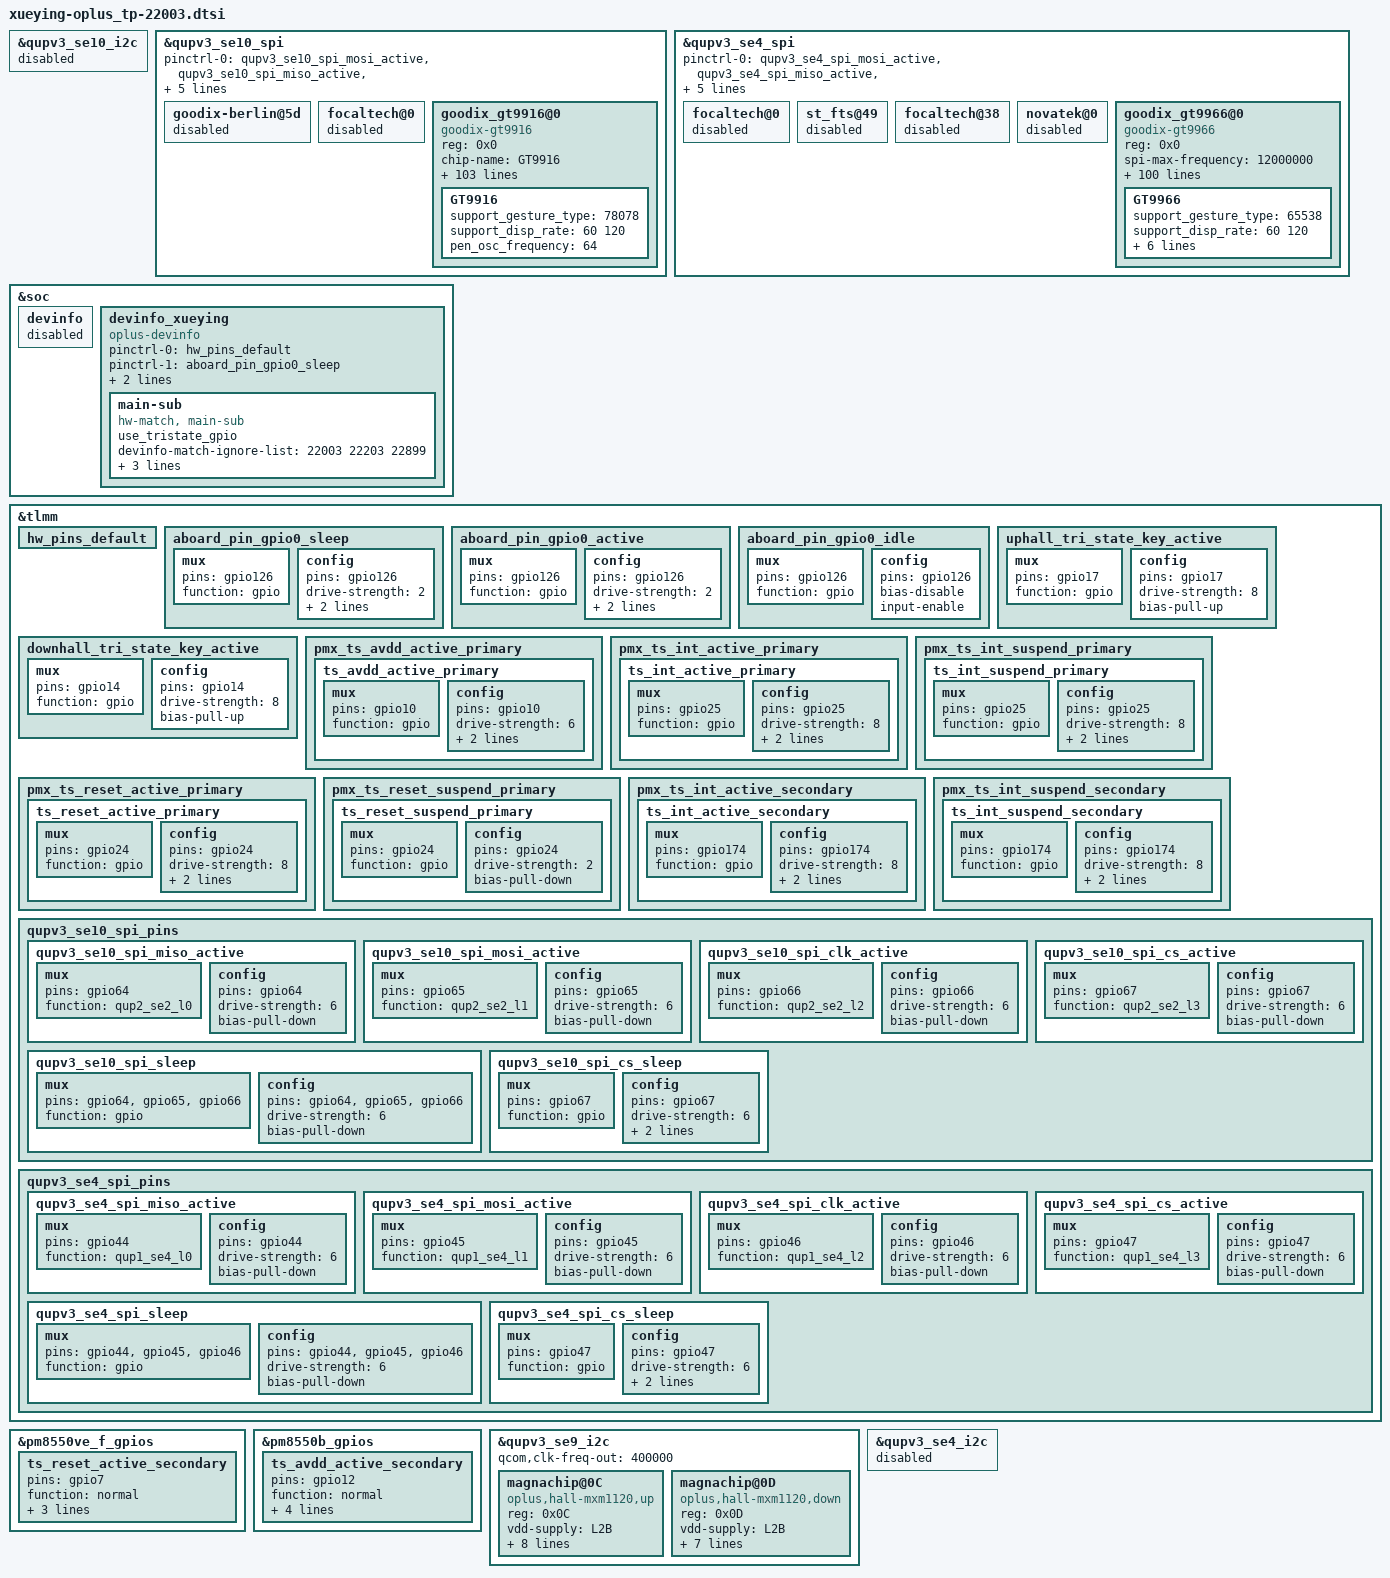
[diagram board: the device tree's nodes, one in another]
&qupv3_se10_i2c {
	status = "disabled";
};

&qupv3_se10_spi{
	/delete-property/ pinctrl-0;
	/delete-property/ pinctrl-1;
	pinctrl-0 = <&qupv3_se10_spi_mosi_active>, <&qupv3_se10_spi_miso_active>,
				<&qupv3_se10_spi_clk_active>, <&qupv3_se10_spi_cs_active>;
	pinctrl-1 = <&qupv3_se10_spi_sleep>, <&qupv3_se10_spi_cs_sleep>;
};

&qupv3_se4_spi{
	/delete-property/ pinctrl-0;
	/delete-property/ pinctrl-1;
	pinctrl-0 = <&qupv3_se4_spi_mosi_active>, <&qupv3_se4_spi_miso_active>,
				<&qupv3_se4_spi_clk_active>, <&qupv3_se4_spi_cs_active>;
	pinctrl-1 = <&qupv3_se4_spi_sleep>, <&qupv3_se4_spi_cs_sleep>;
};

&soc {
    devinfo {
        status = "disabled";
    };

	devinfo_xueying {
		compatible = "oplus-devinfo";

		pinctrl-names = "default", "sleep", "active", "idle";
		pinctrl-0 = <&hw_pins_default>;
		pinctrl-1 = <&aboard_pin_gpio0_sleep>;
		pinctrl-2 = <&aboard_pin_gpio0_active>;
		pinctrl-3 = <&aboard_pin_gpio0_idle>;

		main-sub {
			use_tristate_gpio;
			devinfo-match-ignore-list = <22003 22203 22899>;
			compatible = "hw-match, main-sub";
			aboard-gpio0 = <&tlmm 126 0>;
			aboard-patterns = <0 0 0>;	/*0[high-resistance] 1[pull-down] 2[pull-up]*/
			/*main board*/
			match-projects = <22003 22203 22899>;
		};
	};
};

&tlmm {
//#ifdef OPLUS_FEATURE_TP_BASIC
//#ifdef OPLUS_FEATURE_ABOARD
	hw_pins_default:hw_pins_default {
	};
	aboard_pin_gpio0_sleep:aboard_pin_gpio0_sleep {
		mux {
			pins = "gpio126";
			function = "gpio";
		};
		config {
			pins = "gpio126";
			drive-strength = <2>;
			bias-pull-down;
			input-enable;
		};
	};

	aboard_pin_gpio0_active:aboard_pin_gpio0_active {
		mux {
			pins = "gpio126";
			function = "gpio";
		};
		config {
			pins = "gpio126";
			drive-strength = <2>;
			bias-pull-up;
			input-enable;
		};
	};

	aboard_pin_gpio0_idle:aboard_pin_gpio0_idle {
		mux {
			pins = "gpio126";
			function = "gpio";
		};
		config {
			pins = "gpio126";
			bias-disable;
			input-enable;
		};
	};

//#ifdef OPLUS_FEATURE_TRI_KEY
	uphall_tri_state_key_active: uphall_tri_state_key_active {
		mux {
			pins = "gpio17";
			function = "gpio";
		};
		config {
			pins = "gpio17";
			drive-strength = <8>;
			bias-pull-up;
		};
	};

	downhall_tri_state_key_active: downhall_tri_state_key_active {
		mux {
			pins = "gpio14";
			function = "gpio";
		};
		config {
			pins = "gpio14";
			drive-strength = <8>;
			bias-pull-up;
		};
	};
/*
	gpio_wakeup: gpio_wakeup {
		compatible = "gpio_wakeup";
		gpio_table = <207>;
	};
*/
	/* add primary for touchscreen */
	pmx_ts_avdd_active_primary {
		ts_avdd_active_primary: ts_avdd_active_primary {
			mux {
				pins = "gpio10";
				function = "gpio";
			};

			config {
				pins = "gpio10";
				drive-strength = <6>;
				bias-pull-down;
				input-enable;
			};
		};
	};

	pmx_ts_int_active_primary {
		ts_int_active_primary: ts_int_active_primary {
			mux {
				pins = "gpio25";
				function = "gpio";
			};

			config {
				pins = "gpio25";
				drive-strength = <8>;
				bias-disable;
				input-enable;
			};
		};
	};

	pmx_ts_int_suspend_primary {
		ts_int_suspend_primary: ts_int_suspend_primary {
			mux {
				pins = "gpio25";
				function = "gpio";
			};

			config {
				pins = "gpio25";
				drive-strength = <8>;
				//bias-pull-down;
				bias-pull-up;
				input-enable;
			};
		};
	};

	pmx_ts_reset_active_primary {
		ts_reset_active_primary: ts_reset_active_primary {
			mux {
				pins = "gpio24";
				function = "gpio";
			};

			config {
				pins = "gpio24";
				drive-strength = <8>;
				output-low;
				bias-disable;
			};
		};
	};

	pmx_ts_reset_suspend_primary {
		ts_reset_suspend_primary: ts_reset_suspend_primary {
			mux {
				pins = "gpio24";
				function = "gpio";
			};

			config {
				pins = "gpio24";
				drive-strength = <2>;
				bias-pull-down;
			};
		};
	};
	//#endif

	pmx_ts_int_active_secondary {
		ts_int_active_secondary: ts_int_active_secondary {
			mux {
				pins = "gpio174";
				function = "gpio";
			};

			config {
				pins = "gpio174";
				drive-strength = <8>;
				bias-disable;
				input-enable;
			};
		};
	};

	pmx_ts_int_suspend_secondary {
		ts_int_suspend_secondary: ts_int_suspend_secondary {
			mux {
				pins = "gpio174";
				function = "gpio";
			};

			config {
				pins = "gpio174";
				drive-strength = <8>;
				//bias-pull-down;
				bias-pull-up;
				input-enable;
			};
		};
	};

	qupv3_se10_spi_pins: qupv3_se10_spi_pins {
		qupv3_se10_spi_miso_active: qupv3_se10_spi_miso_active {
			mux {
				pins = "gpio64";
				function = "qup2_se2_l0";
			};

			config {
				pins = "gpio64";
				drive-strength = <6>;
				bias-pull-down;
			};
		};

		qupv3_se10_spi_mosi_active: qupv3_se10_spi_mosi_active {
			mux {
				pins = "gpio65";
				function = "qup2_se2_l1";
			};

			config {
				pins = "gpio65";
				drive-strength = <6>;
				bias-pull-down;
			};
		};

		qupv3_se10_spi_clk_active: qupv3_se10_spi_clk_active {
			mux {
				pins = "gpio66";
				function = "qup2_se2_l2";
			};

			config {
				pins = "gpio66";
				drive-strength = <6>;
				bias-pull-down;
			};
		};

		qupv3_se10_spi_cs_active: qupv3_se10_spi_cs_active {
			mux {
				pins = "gpio67";
				function = "qup2_se2_l3";
			};

			config {
				pins = "gpio67";
				drive-strength = <6>;
				bias-pull-down;
			};
		};

		qupv3_se10_spi_sleep: qupv3_se10_spi_sleep {
			mux {
				pins = "gpio64", "gpio65",
					"gpio66";
				function = "gpio";
			};

			config {
				pins = "gpio64", "gpio65",
					"gpio66";
				drive-strength = <6>;
				bias-pull-down;
			};
		};

		qupv3_se10_spi_cs_sleep: qupv3_se10_spi_cs_sleep {
			mux {
				pins = "gpio67";
				function = "gpio";
			};

			config {
				pins = "gpio67";
				drive-strength = <6>;
				bias-disable;
				output-high;
			};
		};
	};

	qupv3_se4_spi_pins: qupv3_se4_spi_pins {
			qupv3_se4_spi_miso_active: qupv3_se4_spi_miso_active {
					mux {
							pins = "gpio44";
							function = "qup1_se4_l0";
					};

					config {
							pins = "gpio44";
							drive-strength = <6>;
							bias-pull-down;
					};
			};

			qupv3_se4_spi_mosi_active: qupv3_se4_spi_mosi_active {
					mux {
							pins = "gpio45";
							function = "qup1_se4_l1";
					};

					config {
							pins = "gpio45";
							drive-strength = <6>;
							bias-pull-down;
					};
			};

			qupv3_se4_spi_clk_active: qupv3_se4_spi_clk_active {
					mux {
							pins = "gpio46";
							function = "qup1_se4_l2";
					};

					config {
							pins = "gpio46";
							drive-strength = <6>;
							bias-pull-down;
					};
			};

			qupv3_se4_spi_cs_active: qupv3_se4_spi_cs_active {
					mux {
							pins = "gpio47";
							function = "qup1_se4_l3";
					};

					config {
							pins = "gpio47";
							drive-strength = <6>;
							bias-pull-down;
					};
			};

			qupv3_se4_spi_sleep: qupv3_se4_spi_sleep {
					mux {
							pins = "gpio44", "gpio45",
									"gpio46";
							function = "gpio";
					};

					config {
							pins = "gpio44", "gpio45",
									"gpio46";
							drive-strength = <6>;
							bias-pull-down;
					};
			};

			qupv3_se4_spi_cs_sleep: qupv3_se4_spi_cs_sleep {
				mux {
					pins = "gpio47";
					function = "gpio";
				};

				config {
					pins = "gpio47";
					drive-strength = <6>;
					bias-disable;
					output-high;
				};
			};
	};
};

&pm8550ve_f_gpios {
	ts_reset_active_secondary: ts_reset_active_secondary {
		pins = "gpio7";
		function = "normal";
		bias-disable;
		output-low;
		power-source = <1>;
	};
};

&pm8550b_gpios {
	ts_avdd_active_secondary: ts_avdd_active_secondary {
		pins = "gpio12";
		function = "normal";
		input-disable;
		output-enable;
		output-low;
		power-source = <0>;
	};
};

&qupv3_se9_i2c {
	status = "ok";
	qcom,clk-freq-out = <400000>;
	magnachip@0C {
		compatible = "oplus,hall-mxm1120,up";
		reg = <0x0C>;
		vdd-supply = <&L2B>;
		vio-supply = <&L1B>;
		magnachip,init-interval = <200>;
		interrupt-parent = <&tlmm>;
		interrups = <17 0x02>;
		dhall,irq-gpio = <&tlmm 17 0x2008>;
		pinctrl-names = "uphall_tri_state_key_active";
		pinctrl-0 = <&uphall_tri_state_key_active>;
		data_offect = <40>;
		esd-check-support;
	};

	magnachip@0D {
		compatible = "oplus,hall-mxm1120,down";
		reg = <0x0D>;
		vdd-supply = <&L2B>;
		vio-supply = <&L1B>;
		magnachip,init-interval = <200>;
		interrupt-parent = <&tlmm>;
		interrups = <14 0x02>;
		dhall,irq-gpio = <&tlmm 14 0x2008>;
		pinctrl-names = "downhall_tri_state_key_active";
		pinctrl-0 = <&downhall_tri_state_key_active>;
		esd-check-support;
	};
};

//#ifdef /*OPLUS_FEATURE_TP_BASIC*/
&qupv3_se4_i2c {
	status = "disabled";
};
&qupv3_se4_spi {
	status = "ok";
	#address-cells = <1>;
	#size-cells = <0>;

	qcom,spi-touch-active = "goodix-gt9966";
	//qcom,la-vm;

	/delete-node/ focaltech@0;
	focaltech@0 {
		status = "disabled";
	};
	st_fts@49 {
		status = "disabled";
	};
	focaltech@38 {
		status = "disabled";
	};
	novatek@0 {
		status = "disabled";
	};

	goodix_gt9966@0 {
		status = "ok";
		compatible = "goodix-gt9966";
		reg = <0x0>;
		spi-max-frequency = <12000000>;
		chip-num = <3>;
		chip-name = "GT9966DVT", "GT9966", "GT9966";
		/* Interrupt && Irq-gpio */
		irq-gpio = <&tlmm 25 0x2002>;
		interrupt-parent = <&tlmm>;
		interrupts = <25 0x2002>;
		reset-gpio = <&tlmm 24 0x1>;

		/* Power Config */
		enable2v8_gpio = <&tlmm 10 0x1>;
		vcc_1v8-supply = <&L4B>;

		/* Other HW Resource */
		pinctrl-names = "default";
		pinctrl-0 = <&ts_avdd_active_primary &ts_int_active_primary &ts_reset_active_primary>;

		touchpanel,max-num-support = <10>;
		touchpanel,tx-rx-num = <36 38>;
		earsense,tx-rx-num = <36 38>;
		touchpanel,panel-coords = <22680 24400>;
		touchpanel,display-coords = <2268 2440>;
		touchpanel,touchmajor-limit = <128 216>;
		touchpanel,single-optimized-time = <8>;
		touchpanel,high-frame-rate-time = <60>;

		touchpanel,pen-tx-rx-num = <36 38>;
		touchpanel,pen-panel-coords = <22680 24400>;
		touchpanel,pen-max-pressure = <4096>;
		touchpanel,pen-max-tilt = <60 60>;
		touchpanel,msecs-to-jiffies-time = <100>;

		touchpanel,smooth-level = <0 47 45 59 57 131>; /* HighByte:previoueFrame; LowByte:currentFrame */
		//touchpanel,smooth-level-charging = <0 47 45 59 57 131>;
		touchpanel,sensitive-level = <0 90 70 60 57 131>;

		project_id = <22003>;
		vid_len = <2>;
		touchpanel,tp-index = <0>;
		panel_type = <3 8 3>; // type of tp_dev ,TP-BOE = 3;
		firmware_name = "AC052", "AC052", "AC052";
		platform_support_project = <22003 22203 22899>;
		platform_support_project_dir = <22003 22003 22003>;
		platform_support_project_commandline = "dsi_panel_AC052_P_3_A0003_dsc_cmd_dvt",
						     "dsi_panel_AC052_P_1_A0002_dsc_cmd",
						     "dsi_panel_AC052_P_3_A0003_dsc_cmd";

		prevention,curved_screen_V2;
		prevention,grip_disable_level = <6>;
		prevention,updelay_time_ms = <30>;
		prevention,makeup_cnt_weight = <5 1 2 2 2>;
		prevention,large_corner_range = <1200 3000>;
		prevention,large_corner_judge_condition = <500 100 1000 7 7>;
		prevention,trx_reject_condition = <9 7 5>;
		prevention,trx_strict_reject_condition = <8 5 5>;
		prevention,large_judge_time_ms = <500 50 100>;
		prevention,large_exit_condition = <8 8 2>;
		prevention,single_channel_width = <320 320>;
		prevention,normal_tap_condition = <10 350>;
		prevention,long_edge_condition = <200 150 40 80>;
		prevention,long_strict_edge_condition = <50 25>;
		prevention,long_fingerhold_condition = <70 6 4 4>;
		prevention,short_edge_condition = <250 90 180 80>;
		prevention,short_strict_edge_condition = <160 60>;
		prevention,large_strict_exit_condition = <4 4>;
		prevention,top_corner_config = <500 1500 300>;
		prevention,edge_swipe_config = <300 1000>;

		prevention,curved_screen_V4;
		prevention,long_eliminate_point_type = <2 22680 8400 300 24400 300 1>;
		prevention,long_fingerhold_condition2 = <650 2000 0 0>;
		prevention,top_corner_config2 = <3 80 600 1500 0>;
		prevention,hor_long_top_corner_config = <350 2270 0 0>;
		prevention,top_middle_config = <22680 1000 1000 0>;
		prevention,corner_eliminate_point_type = <0 1380 2280 1>;
		prevention,finger_hold_differ_size = <1 0 300 300>;
		prevention,finger_hold_max_rx_exit_distance = <5 350 2300>;
		prevention,max_rx_exit_distance = <1 5 150 350 2000>;
		prevention,dynamic_finger_hold_exit_distance = <1 350 2300 450>;

		black_gesture_support;
		pressure_report_support;
		charger_pump_support;
		game_switch_support;
		smart_gesture_support;
		spi_port_support;
		fw_update_app_support;
		//fingerprint_underscreen_support;
		//freq_hop_simulate_support;
		report_flow_unlock_support;
		//screenoff_fingerprint_info_support;
		irq_need_dev_resume_ok;
		//enable_point_auto_change;
		//report_rate_white_list_support;
		kernel_grip_support;
		exception_upload_support;
		//grip_no_driver_support;
		health_monitor_support;
		black_gesture_indep_support;
		//algorithm_support;
		//snr_read_support;
		//touchpanel,get_motor_coord = <0 370 70>;
		sportify_aod_gesture_support;
		temperature_detect_shellback_support;
		pen_support;
		pen_support_opp;
		bus_ready_check_support;
		tp_lcd_suspend_in_lp_support;
		/*
		 *Virtual Key Config:
		 *1:touchpanel,button-type: <virtualkey_type  supportted_button-map>
		 *virtualkey_type:
		 *Type 1: using board_properties
		 *Type 2: using same IC (button zone&& touch zone are seprate)
		 *Type 3: using diffrent IC (button zone&& touch zone are seprate)
		 *Type 4: No need of virtual key process
		 *supportted_button-map:select|menu|home|back
		 *
		 *2:touchpanel,button-map
		 *type (X1,Y1)(X2,Y2)(X3,Y3)(Width_X,Hight_Y)--Only when button-type is 0
		 */
		touchpanel,button-type = <4>;
		touchpanel.button-TRx = <0 0>;

		GT9966 {
			support_gesture_type = <65538>;
			support_disp_rate = <60 120>;
			pen_osc_frequency = <64>; /*16m or 64m osc clk for factory test*/
			need_change_trx_name = "SAMSUNG";
			SAMSUNG = <38 41>;
			need_change_clk_name = "SAMSUNG_CLK";
			SAMSUNG_CLK = <16>;
			hardware_trx_direction = <1>;/* 0:left,right:tx up,down:rx
							1:left,right:rx up,down:tx
							'when usb port faces down' */
		};
	};
//#endif /*OPLUS_FEATURE_TP_BASIC*/
};

&qupv3_se10_spi {
	status = "ok";

	qcom,spi-touch-active = "goodix-gt9916";

	#address-cells = <1>;
	#size-cells = <0>;

	/delete-node/ focaltech@0;

	goodix-berlin@5d {
		status = "disabled";
	};

	focaltech@0 {
		status = "disabled";
	};

	goodix_gt9916@0{
		compatible = "goodix-gt9916";
		reg = <0x0>;
		chip-name = "GT9916";
		status = "ok";
		spi-max-frequency = <12000000>;

		/* Interrupt && Irq-gpio */
		irq-gpio = <&tlmm 174 0x2002>;
		interrupt-parent = <&tlmm>;
		interrupts = <174 0x2002>;

		/* Power Config */
		enable2v8_gpio = <&pm8550b_gpios 12 0x1>;
		vcc_1v8-supply = <&L4B>;

		/* Other HW Resource */
		reset-gpio = <&pm8550ve_f_gpios 7 0x1>;

		pinctrl-names = "default";
		pinctrl-0 = <&ts_avdd_active_secondary &ts_int_active_secondary &ts_reset_active_secondary>;

		touchpanel,max-num-support = <10>;
		touchpanel,tx-rx-num = <18 40>;
		earsense,tx-rx-num = <18 40>;
		touchpanel,panel-coords = <11160 24840>;
		touchpanel,display-coords = <1116 2484>;
		touchpanel,touchmajor-limit = <256 256>;
		touchpanel,curved-size = <45>;

		touchpanel,single-optimized-time = <8>;
		touchpanel,high-frame-rate-time = <60>;

		touchpanel,pen-tx-rx-num = <18 40>;
		touchpanel,pen-panel-coords = <11160 24840>;
		touchpanel,pen-max-pressure = <4096>;
		touchpanel,pen-max-tilt = <60 60>;
		touchpanel,msecs-to-jiffies-time = <100>;

		touchpanel,smooth-level = <0 95 115 135 165 205>;
		touchpanel,smooth-level-charging = <0 111 142 163 219 231>;
		touchpanel,sensitive-level = <0 90 70 60 40 31>;

		project_id = <22003>;
		vid_len = <2>;
		touchpanel,tp-index = <1>;
		panel_type = <3>; // type of tp_dev ,TP-BOE = 3;
		firmware_name = "AC052", "AC052", "AC052";
		platform_support_project = <22003 22203 22899>;
		platform_support_project_dir = <22003 22003 22003>;
		platform_support_project_commandline = "dsi_panel_AC052_S_3_A0001_dsc_cmd";

		prevention,curved_screen_V2;
		prevention,grip_disable_level = <6>;
		prevention,updelay_time_ms = <30>;
		prevention,makeup_cnt_weight = <5 1 2 2 2>;
		prevention,large_corner_range = <1200 3000>;
		prevention,large_corner_judge_condition = <500 100 1000 7 7>;
		prevention,trx_reject_condition = <9 7 7>;
		prevention,trx_strict_reject_condition = <8 5 5>;
		prevention,large_judge_time_ms = <500 50 100>;
		prevention,large_exit_condition = <8 8 2>;
		prevention,single_channel_width = <320 320>;
		prevention,normal_tap_condition = <10 350>;
		prevention,long_edge_condition = <120 150 60 80>;
		prevention,long_strict_edge_condition = <50 25>;
		prevention,long_fingerhold_condition = <70 6 4 4>;
		prevention,short_edge_condition = <250 90 180 80>;
		prevention,short_strict_edge_condition = <160 60>;
		prevention,large_strict_exit_condition = <4 4>;
		prevention,top_corner_config = <500 1500 300>;
		prevention,edge_swipe_config = <300 1000>;

		prevention,curved_screen_V4;
		prevention,long_eliminate_point_type = <2 11160 8280 300 24840 300 1>;
		prevention,long_fingerhold_condition2 = <650 2000 0 0>;
		prevention,top_corner_config2 = <3 80 600 1500 0>;
		prevention,hor_long_top_corner_config = <350 2270 0 0>;
		prevention,top_middle_config = <11160 1000 1000 0>;
		prevention,corner_eliminate_point_type = <0 1380 2280 1>;
		prevention,finger_hold_differ_size = <1 0 300 300>;
		prevention,finger_hold_max_rx_exit_distance = <5 350 2300>;
		prevention,max_rx_exit_distance = <1 5 150 350 2000>;
		prevention,dynamic_finger_hold_exit_distance = <1 350 2300 450>;
		prevention,large_corner_judge_condition_ime = <300 0 0 0 0>;

		black_gesture_support;
		pressure_report_support;
		charger_pump_support;
		game_switch_support;
		smart_gesture_support;
		spi_port_support;
		fw_update_app_support;
		//fingerprint_underscreen_support;
		//freq_hop_simulate_support;
		report_flow_unlock_support;
		//screenoff_fingerprint_info_support;
		irq_need_dev_resume_ok;
		//enable_point_auto_change;
		//report_rate_white_list_support;
		kernel_grip_support;
		exception_upload_support;
		//grip_no_driver_support;
		health_monitor_support;
		black_gesture_indep_support;
		//algorithm_support;
		//snr_read_support;
		//touchpanel,get_motor_coord = <0 370 70>;
		sportify_aod_gesture_support;
		pen_support;
		pen_support_opp;
		palm_to_sleep_support;
		temperature_detect_shellback_support;
		bus_ready_check_support;
		tp_lcd_suspend_in_lp_support;
		/*
		 *Virtual Key Config:
		 *1:touchpanel,button-type: <virtualkey_type  supportted_button-map>
		 *virtualkey_type:
		 *Type 1: using board_properties
		 *Type 2: using same IC (button zone&& touch zone are seprate)
		 *Type 3: using diffrent IC (button zone&& touch zone are seprate)
		 *Type 4: No need of virtual key process
		 *supportted_button-map:select|menu|home|back
		 *
		 *2:touchpanel,button-map
		 *type (X1,Y1)(X2,Y2)(X3,Y3)(Width_X,Hight_Y)--Only when button-type is 0
		 */
		touchpanel,button-type = <4>;
		touchpanel.button-TRx = <0 0>;

		GT9916 {
			support_gesture_type = <78078>;
			support_disp_rate = <60 120>;
			pen_osc_frequency = <64>; /*16m or 64m osc clk for factory test*/
		};
	};
};
//#endif /*OPLUS_FEATURE_TP_BASIC*/
